# M066 register map
File version: 0.1
TOSHIBA Cortex-M3 MCU
Registers are 32-bit, read-write, reset 0x0 unless marked. A register's access mark holds for its fields unless they carry their own. Offsets are from the block's base; lines under a group give offsets from that group; [hi:lo] are bit positions; {n}, {i} and the like mark numbered series; 'fields as' and 'values as' point back to an identical list; <NAME> marks a mode.

## Memory map
0x40008000 UDFS blocks up to offset 0x8C — UDC2 AHB Bridge
0x40008200 UDFS2 blocks up to offset 0x138 — UDC2(USB -Spec2.0 Device contoller)
0x40038000 INTIFAO blocks up to offset 0x28 — AO Area register1
0x40038400 AOREG blocks up to offset 0x4 — AO Area register2
0x40038800 I2CS size 0x4 — I2C Wakeup I_F register
0x4004C000 DMA blocks up to offset 0x50 — DMA Controller
0x40058000 TD0 blocks up to offset 0x168 — Timer D (Unit0)
0x4005802C TD1 blocks up to offset 0x144 — Timer D (Unit1)
0x40058040 TD blocks up to offset 0x18 — Timer D common
0x4008D000 T16A0 size 0x14 — 16-bit TimerA
0x4008E000 T16A1 size 0x14
0x40098000 TSPI blocks up to offset 0x208 — Serial Interface (TSPI)
0x400A0000 I2C0 size 0x28 — I2C
0x400A1000 I2C1 size 0x28
0x400C0000 PA blocks up to offset 0x3C — Port A
0x400C0100 PB blocks up to offset 0x3C — Port B
0x400C0200 PC blocks up to offset 0x3C — Port C
0x400C0300 PD blocks up to offset 0x3C — Port D
0x400C0400 PE blocks up to offset 0x3C — Port E
0x400C0500 PF blocks up to offset 0x3C — Port F
0x400C0600 PG blocks up to offset 0x3C — Port G
0x400C0700 PH blocks up to offset 0x3C — Port H
0x400C0800 PJ blocks up to offset 0x3C — Port J
0x400C4000 TB0 size 0x34 — 16-bit Timer_Event Counter (TB)
0x400C4100 TB1 size 0x34
0x400C4200 TB2 size 0x34
0x400C4300 TB3 size 0x34
0x400C4400 TB4 size 0x34
0x400C4500 TB5 size 0x34
0x400C4600 TB6 size 0x34
0x400C4700 TB7 size 0x34
0x400E1000 SC0 size 0x38 — SC
0x400E1100 SC1 size 0x38
0x400F2000 WD size 0xC — WDT
0x400F3000 CG blocks up to offset 0x64
0x400F4000 LVD size 0x8
0x400F4E00 INTIFSD blocks up to offset 0x118 — SD Area register1
0x400FC000 AD blocks up to offset 0x6C — ADC
0x41FFF000 FC blocks up to offset 0x3C

## UDFS — UDC2 AHB Bridge
Base 0x40008000
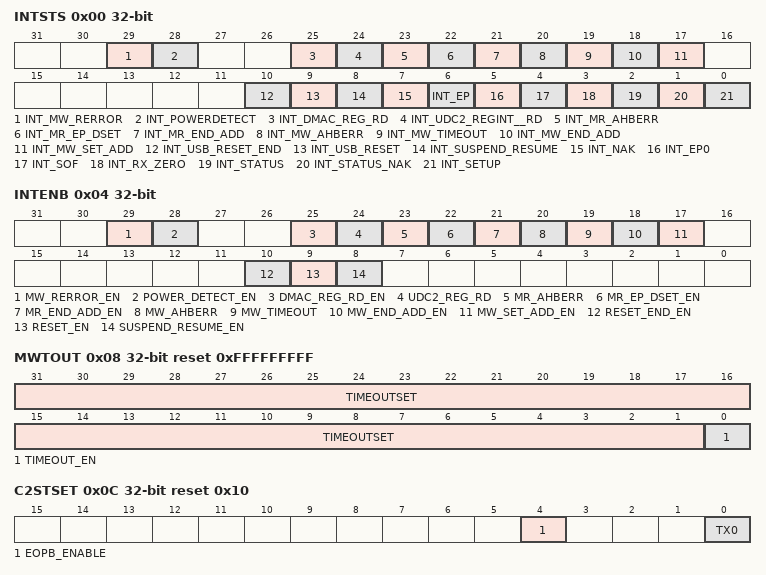
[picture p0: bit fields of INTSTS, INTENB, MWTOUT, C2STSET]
0x00 INTSTS — Interrupt Status Register
  [29] INT_MW_RERROR, [28] INT_POWERDETECT, [25] INT_DMAC_REG_RD, [24] INT_UDC2_REGINT__RD, [23] INT_MR_AHBERR, [22] INT_MR_EP_DSET, [21] INT_MR_END_ADD, [20] INT_MW_AHBERR, [19] INT_MW_TIMEOUT, [18] INT_MW_END_ADD, [17] INT_MW_SET_ADD, [10] INT_USB_RESET_END, [9] INT_USB_RESET, [8] INT_SUSPEND_RESUME, [7] INT_NAK ro, [6] INT_EP ro, [5] INT_EP0 ro, [4] INT_SOF ro, [3] INT_RX_ZERO ro, [2] INT_STATUS ro, [1] INT_STATUS_NAK ro, [0] INT_SETUP ro
0x04 INTENB — Interrupt Enable Register
  [29] MW_RERROR_EN, [28] POWER_DETECT_EN, [25] DMAC_REG_RD_EN, [24] UDC2_REG_RD, [23] MR_AHBERR, [22] MR_EP_DSET_EN, [21] MR_END_ADD_EN, [20] MW_AHBERR, [19] MW_TIMEOUT, [18] MW_END_ADD_EN, [17] MW_SET_ADD_EN, [10] RESET_END_EN, [9] RESET_EN, [8] SUSPEND_RESUME_EN
0x08 MWTOUT reset 0xFFFFFFFFF — Master Write Timeout Register
  [31:1] TIMEOUTSET, [0] TIMEOUT_EN
0x0C C2STSET reset 0x10 — UDC2 setting
  [4] EOPB_ENABLE, [0] TX0
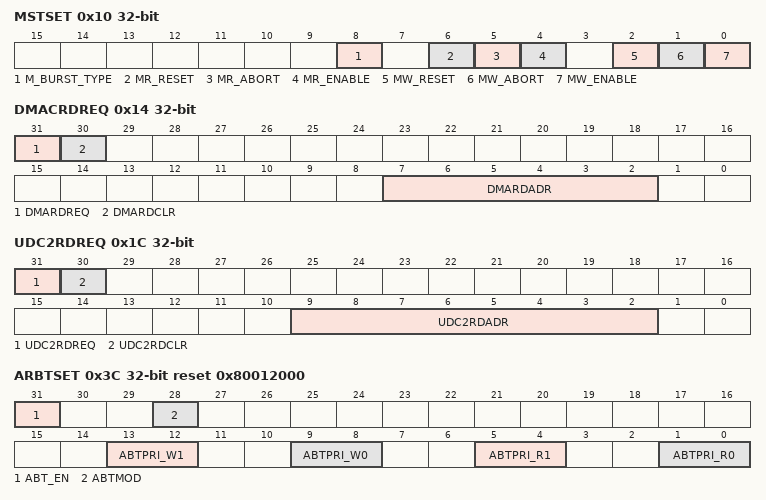
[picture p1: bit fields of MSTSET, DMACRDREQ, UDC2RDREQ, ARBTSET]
0x10 MSTSET — DMAC setting
  [8] M_BURST_TYPE, [6] MR_RESET, [5] MR_ABORT wo, [4] MR_ENABLE, [2] MW_RESET, [1] MW_ABORT wo, [0] MW_ENABLE
0x14 DMACRDREQ — DMAC Read request
  [31] DMARDREQ, [30] DMARDCLR, [7:2] DMARDADR
0x18 DMACRDVL ro — DMAC Read Value
  [31:0] DMARDDATA
0x1C UDC2RDREQ — UDC2 Read Request
  [31] UDC2RDREQ, [30] UDC2RDCLR, [9:2] UDC2RDADR
0x20 UDC2RDVL ro — UDC2 Read Value
  [15:0] UDC2RDATA
0x3C ARBTSET reset 0x80012000 — Arbiter Setting
  [31] ABT_EN, [28] ABTMOD, [13:12] ABTPRI_W1, [9:8] ABTPRI_W0, [5:4] ABTPRI_R1 ro, [1:0] ABTPRI_R0
0x40 MWSADR reset 0xFFFFFFFF — Master Write Start Address
0x44 MWEADR reset 0xFFFFFFFF — Master Write End Address
0x48 MWCADR ro reset 0xFFFFFFFF — Master Write Current Address
0x4C MWAHBADR ro reset 0xFFFFFFFF — Master Write AHB Address
0x50 MRSADR reset 0xFFFFFFFF — Master Read Start Address
0x54 MREADR reset 0xFFFFFFFF — Master Read End Address
0x58 MRCADR ro reset 0xFFFFFFFF — Master Read Current Address
0x5C MRAHBADR ro reset 0xFFFFFFFF — Master Read AHB Address
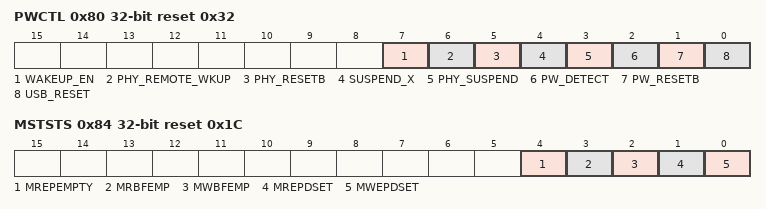
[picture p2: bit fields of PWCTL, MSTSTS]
0x80 PWCTL reset 0x32 — Power Detect Control
  [7] WAKEUP_EN, [6] PHY_REMOTE_WKUP, [5] PHY_RESETB, [4] SUSPEND_X ro, [3] PHY_SUSPEND, [2] PW_DETECT ro, [1] PW_RESETB, [0] USB_RESET ro
0x84 MSTSTS ro reset 0x1C — Master Status
  [4] MREPEMPTY, [3] MRBFEMP, [2] MWBFEMP, [1] MREPDSET, [0] MWEPDSET
0x88 TOUTCNT ro reset 0xFFFFFFFF — Timeout Count
  [31:0] TMOUTCNT
